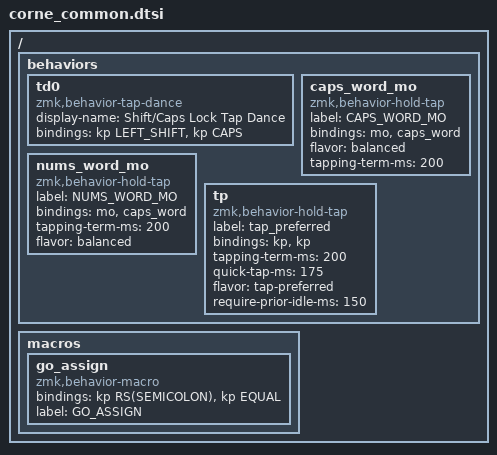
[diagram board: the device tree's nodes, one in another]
#include <dt-bindings/zmk/mouse.h>
#include <input/processors.dtsi>
#include <behaviors.dtsi>
#include <dt-bindings/zmk/bt.h>
#include <dt-bindings/zmk/keys.h>
#include <dt-bindings/zmk/outputs.h>
#include <dt-bindings/zmk/pointing.h>
#include <dt-bindings/zmk/rgb.h>

/*

   &mmv_input_listener {
       input-processors = <&zip_xy_scaler 2 1>;
   };

   &msc_input_listener {
       input-processors = <&zip_xy_scaler 2 1>;
   };

 */

#define ZMK_MOUSE_DEFAULT_MOVE_VAL 1200  // 600
#define ZMK_MOUSE_DEFAULT_SCRL_VAL 20    // 10

/ {
    behaviors {
        td0: td0 {
            compatible = "zmk,behavior-tap-dance";
            display-name = "Shift/Caps Lock Tap Dance";
            #binding-cells = <0>;
            bindings = <&kp LEFT_SHIFT>, <&kp CAPS>;
        };

        caps_word_mo: caps_word_mo {
            compatible = "zmk,behavior-hold-tap";
            label = "CAPS_WORD_MO";
            bindings = <&mo>, <&caps_word>;

            #binding-cells = <2>;
            flavor = "balanced";
            tapping-term-ms = <200>;
        };

        nums_word_mo: nums_word_mo {
            compatible = "zmk,behavior-hold-tap";
            label = "NUMS_WORD_MO";
            bindings = <&mo>, <&caps_word>;

            #binding-cells = <2>;
            tapping-term-ms = <200>;
            flavor = "balanced";
        };

        tp: tp {
            compatible = "zmk,behavior-hold-tap";
            label = "tap_preferred";
            bindings = <&kp>, <&kp>;

            #binding-cells = <2>;
            tapping-term-ms = <200>;
            quick-tap-ms = <175>;
            flavor = "tap-preferred";
            require-prior-idle-ms = <150>;
        };
    };

    macros {
        go_assign: go_assign {
            compatible = "zmk,behavior-macro";
            #binding-cells = <0>;
            bindings = <&kp RS(SEMICOLON) &kp EQUAL>;
            label = "GO_ASSIGN";
        };
    };
};
